AUTOSAR XML (schema 00048)
package /HuaweiMDC/FunctionalSoftware/Control/Execution
  executable ControlExecutable
    root sw component prototype ControlRootSwComponent: application-type=ControlApplicationSwComponent
package /HuaweiMDC/FunctionalSoftware/Control/SwComponent
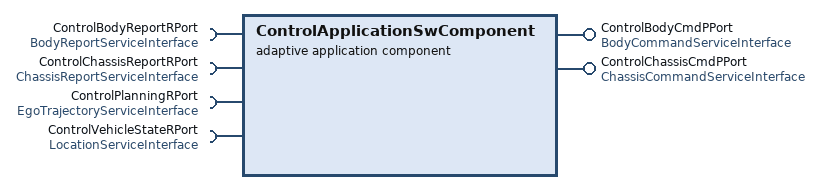
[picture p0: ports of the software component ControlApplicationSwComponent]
  adaptive application sw component type ControlApplicationSwComponent
    provide port ControlBodyCmdPPort: provided-interface=BodyCommandServiceInterface
    require port ControlBodyReportRPort: required-interface=BodyReportServiceInterface
    provide port ControlChassisCmdPPort: provided-interface=ChassisCommandServiceInterface
    require port ControlChassisReportRPort: required-interface=ChassisReportServiceInterface
    require port ControlPlanningRPort: required-interface=EgoTrajectoryServiceInterface
    require port ControlVehicleStateRPort: required-interface=LocationServiceInterface
